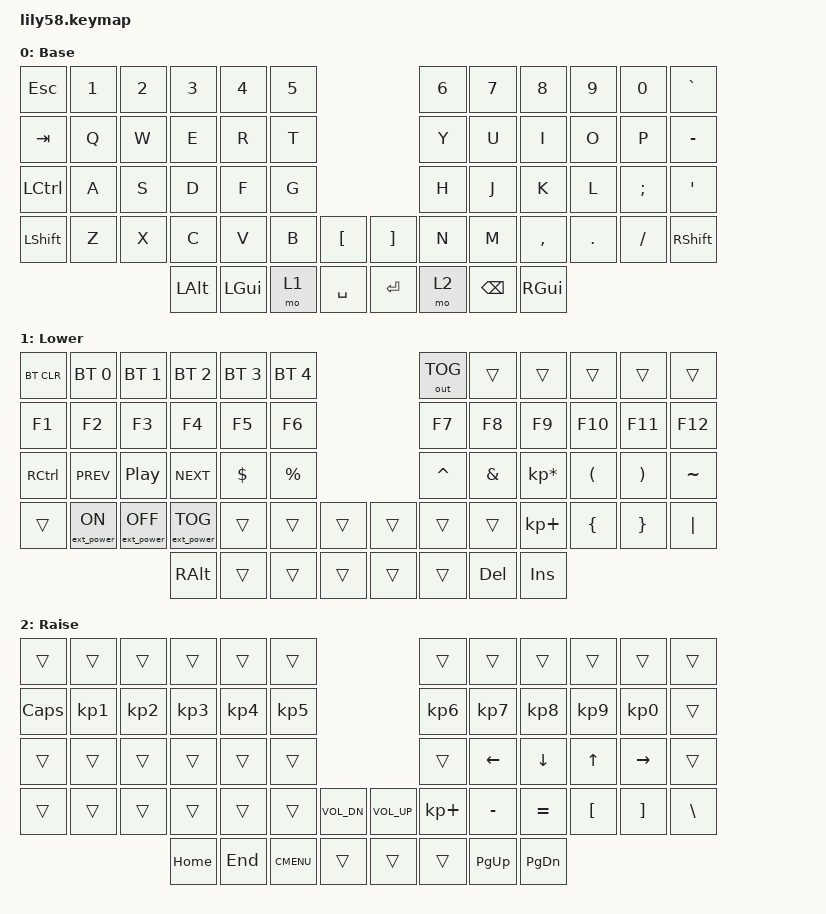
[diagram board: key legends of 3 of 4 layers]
/*
 * Copyright (c) 2020 The ZMK Contributors
 *
 * SPDX-License-Identifier: MIT
 */

#include <behaviors.dtsi>
#include <dt-bindings/zmk/keys.h>
#include <dt-bindings/zmk/bt.h>
#include <dt-bindings/zmk/ext_power.h>
#include <dt-bindings/zmk/outputs.h>

#define DEFAULT 0
#define LOWER   1
#define RAISE   2
#define ADJUST  3

/ {
	conditional_layers {
        compatible = "zmk,conditional-layers";
        adjust_layer {
            if-layers = <LOWER RAISE>;
            then-layer = <ADJUST>;
        };
    };

	keymap {
		compatible = "zmk,keymap";

		default_layer {
// ------------------------------------------------------------------------------------------------------------
// |  ESC  |  1  |  2  |  3   |  4   |  5   |                   |  6   |  7    |  8    |  9   |   0   |   `   |
// |  TAB  |  Q  |  W  |  E   |  R   |  T   |                   |  Y   |  U    |  I    |  O   |   P   |   -   |
// |  CTRL |  A  |  S  |  D   |  F   |  G   |                   |  H   |  J    |  K    |  L   |   ;   |   '   |
// | SHIFT |  Z  |  X  |  C   |  V   |  B   |   "["  |  |  "]"  |  N   |  M    |  ,    |  .   |   /   | SHIFT |
//                     | ALT | GUI |LOWER|  SPACE |  | ENTER |RAISE| BSPC | GUI  |
			label = "Base";
			bindings = <
&kp ESC   &kp N1 &kp N2 &kp N3   &kp N4   &kp N5                     &kp N6 &kp N7   &kp N8    &kp N9  &kp N0   &kp GRAVE
&kp TAB   &kp Q  &kp W  &kp E    &kp R    &kp T                      &kp Y  &kp U    &kp I     &kp O   &kp P    &kp MINUS
&kp LCTRL &kp A  &kp S  &kp D    &kp F    &kp G                      &kp H  &kp J    &kp K     &kp L   &kp SEMI &kp SQT
&kp LSHFT &kp Z  &kp X  &kp C    &kp V    &kp B  &kp LBKT   &kp RBKT &kp N  &kp M    &kp COMMA &kp DOT &kp FSLH &kp RSHFT
                        &kp LALT &kp LGUI &mo 1  &kp SPACE  &kp RET  &mo 2  &kp BSPC &kp RGUI
			>;

			sensor-bindings = <&inc_dec_kp C_VOL_UP C_VOL_DN>;
		};

		lower_layer {
// ------------------------------------------------------------------------------------------------------------
// | BTCLR | BT1  | BT2  |  BT3 |  BT4 |  BT5 |                 |OUT TOGGLE|	 	|		|       |      |       |
// |  F1   |  F2  |  F3  |  F4  |  F5  |  F6  |                 |    F7    |   F8   |  F9   |  F10  |  F11 |  F12  |
// | RCTRL |C_PREV|C_PP  |C_NEXT|  $   |  %   |                 |    ^     |   &    |  *    |  (    |   )  |   ~   |
// |       |EP_ON |EP_OFF|EP_TOG|      |      |       |  |      |          |        |  +    |  {    |   }  |  "|"  |
//                       | RALT |      |      |       |  |      |          |   DEL  |INSERT |
			label = "Lower";
			bindings = <
&bt BT_CLR &bt BT_SEL 0	&bt BT_SEL 1 &bt BT_SEL 2 &bt BT_SEL 3 &bt BT_SEL 4						&out OUT_TOG  &trans  &trans &trans  &trans  &trans
&kp F1 &kp F2 &kp F3 &kp F4 &kp F5 &kp F6        												&kp F7 &kp F8 &kp F9 &kp F10 &kp F11 &kp F12
&kp RCTRL &kp C_PREV &kp C_PP &kp C_NEXT &kp DOLLAR &kp PRCNT      		 						&kp CARET &kp AMPS &kp KP_MULTIPLY &kp LPAR &kp RPAR &kp TILDE
&trans &ext_power EP_ON &ext_power EP_OFF &ext_power EP_TOG &trans &trans &trans &trans      	&trans &trans &kp KP_PLUS &kp LBRC &kp RBRC &kp PIPE 
					&kp RALT &trans &trans &trans     											&trans &trans &kp DEL &kp INSERT
			>;

			sensor-bindings = <&inc_dec_kp C_VOL_UP C_VOL_DN>;
		};

		raise_layer {
// ------------------------------------------------------------------------------------------------------------
// |     |      |      |     |     |       |           		    |     |      |      |       |       |       |
// |CAPS |   1  |  2   |  3  |  4  |  5    |                    |  6  |   7  |   8  |  9    |   0   |       |
// |     | 	    |      |     |     |       |                    |     |   <- |   ^  |  v    |  ->   |       |
// |     |      |      |     |     |       |C_VOL_DN|  |C_VOL_UP|  +  |   -  |   =  |  [    |   ]   |   \   |
//                     |HOME | END |SUBMENU|        |  |        |     |      |PG UP |PG DOWN|
			label = "Raise";
			bindings = <
&trans &trans &trans &trans &trans &trans          				&trans  &trans  &trans &trans   &trans    &trans
&kp CAPS &kp KP_N1 &kp KP_N2 &kp KP_N3 &kp KP_N4 &kp KP_N5		&kp KP_N6 &kp KP_N7 &kp KP_N8 &kp KP_N9 &kp KP_N0 &trans
&trans &trans &trans &trans  &trans  &trans 					&trans &kp LEFT &kp DOWN &kp UP &kp RIGHT &trans
&trans &trans &trans &trans &trans &trans &kp C_VOL_DN      &kp C_VOL_UP &kp KP_PLUS &kp MINUS &kp EQUAL &kp LBKT &kp RBKT &kp BSLH
                        &kp HOME &kp END &kp K_CMENU &trans         	&trans &trans &kp PG_UP &kp PG_DN
			>;

			sensor-bindings = <&inc_dec_kp C_VOL_UP C_VOL_DN>;
		};

		media_layer {
// -----------------------------------------------------------------------------------------
// |     |      |      |     |     |       |           		    |     |      |      |       |       |       |
// |     |      |      |     |     |       |           		    |     |      |      |       |       |       |
// |     |      |      |     |     |       |           		    |     |      |      |       |       |       |
// |     |      |      |     |     |       |           		    |     |      |      |       |       |       |
//                     |     |     |       |        |  |        |     |      |      |       |
			label = "Media";
			bindings = <
&trans &trans &trans &trans &trans &trans          				&trans  &trans  &trans &trans   &trans    &trans
&trans &trans &trans &trans &trans &trans          				&trans  &trans  &trans &trans   &trans    &trans
&trans &trans &trans &trans &trans &trans          				&trans  &trans  &trans &trans   &trans    &trans
&trans &trans &trans &trans &trans &trans          				&trans  &trans  &trans &trans   &trans    &trans
					&trans &trans   &trans    &trans   		&trans &trans   &trans    &trans
			>;
		};
	};
};
